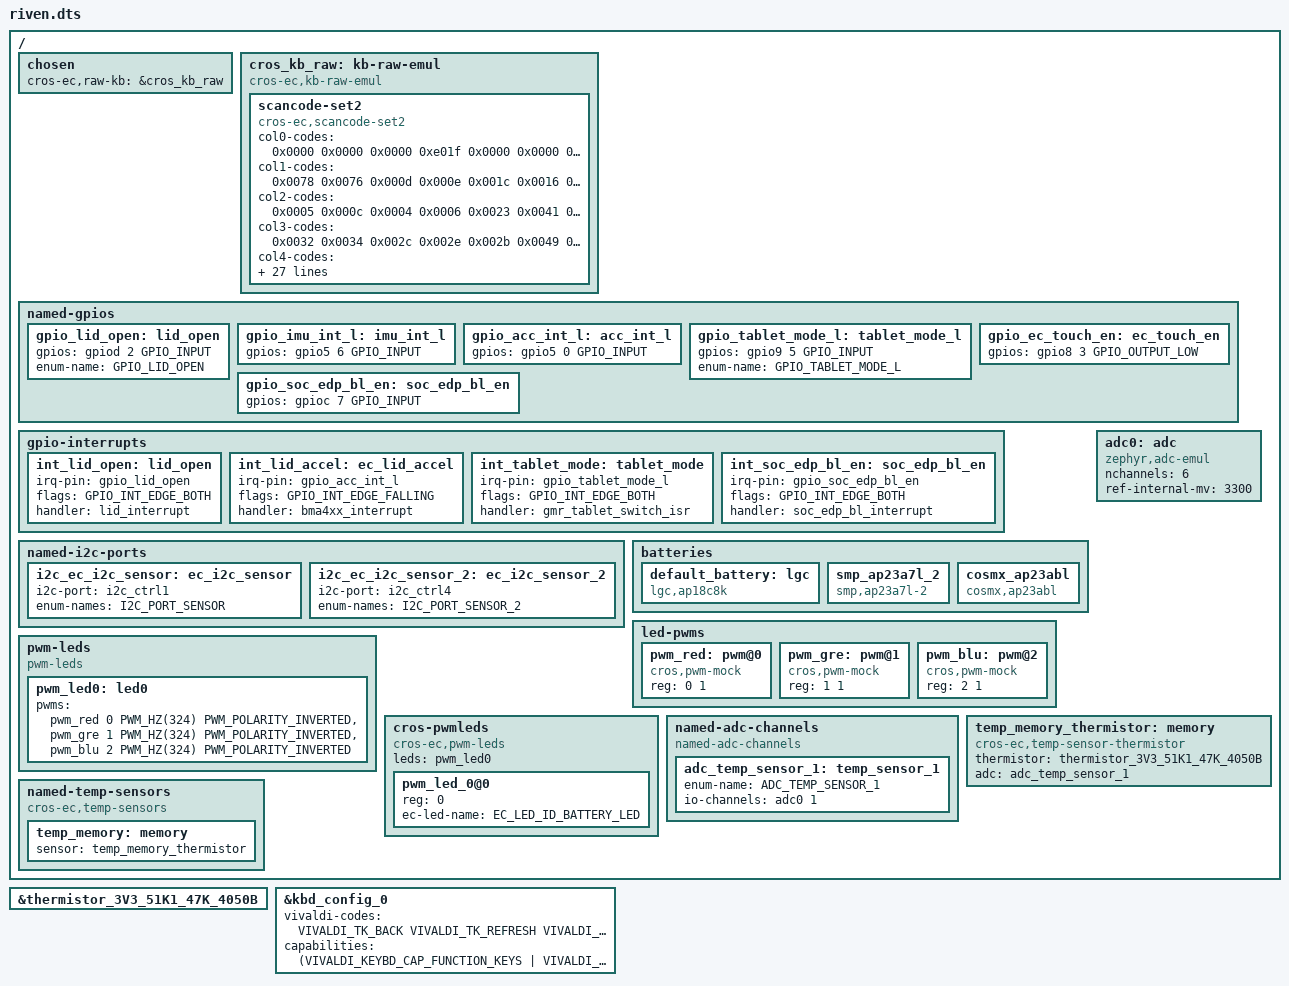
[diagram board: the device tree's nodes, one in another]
/* Copyright 2024 The ChromiumOS Authors
 * Use of this source code is governed by a BSD-style license that can be
 * found in the LICENSE file.
 */

#include <cros/thermistor/thermistor.dtsi>
#include <dt-bindings/pwm/pwm.h>
#include <cros/vivaldi_kbd_default.dtsi>

#include "generic_npcx.dts"
#include "../program/nissa/riven/cbi.dtsi"
#include "../program/nissa/riven/motionsense.dtsi"

/ {
	chosen {
		cros-ec,raw-kb = &cros_kb_raw;
	};

	cros_kb_raw: kb-raw-emul {
		compatible = "cros-ec,kb-raw-emul";
		scancode-set2 {
			compatible = "cros-ec,scancode-set2";
			col0-codes  = <0x0000 0x0000 0x0000 0xe01f 0x0000 0x0000 0x0000 0x0000>;
			col1-codes  = <0x0078 0x0076 0x000d 0x000e 0x001c 0x0016 0x001a 0x003c>;
			col2-codes  = <0x0005 0x000c 0x0004 0x0006 0x0023 0x0041 0x0026 0x0043>;
			col3-codes  = <0x0032 0x0034 0x002c 0x002e 0x002b 0x0049 0x0025 0x0044>;
			col4-codes  = <0x0009 0x0083 0x000b 0x001b 0x0003 0x004a 0x001e 0x004d>;
			col5-codes  = <0x0031 0x0007 0x005b 0x000f 0x0042 0x0021 0x003e 0x0015>;
			col6-codes  = <0x0051 0x0033 0x0035 0x004e 0x003b 0x0029 0x0045 0x001d>;
			col7-codes  = <0x0000 0x0000 0x0000 0x0000 0x0000 0x0012 0x0000 0x0059>;
			col8-codes  = <0x0055 0x0052 0x0054 0x0036 0x004c 0x0022 0x003d 0x0024>;
			col9-codes  = <0xe06c 0x0001 0xe071 0x002f 0x004b 0x002a 0x0046 0x002d>;
			col10-codes = <0xe011 0x0000 0x006a 0x0000 0x005d 0x0000 0x0000 0x0000>;
			col11-codes = <0x0017 0x0066 0x000a 0x005d 0x005a 0x003a 0xe072 0xe075>;
			col12-codes = <0x001f 0x0064 0xe07d 0x0067 0xe069 0xe07a 0xe074 0xe06b>;
			col13-codes = <0x0000 0x0000 0x0000 0x0000 0x0000 0x0000 0x0011 0x0000>;
			col14-codes = <0x0000 0x0014 0x0000 0xe014 0x0000 0x0000 0x0000 0x0000>;
			col15-codes = <0x0000 0x0000 0x0000 0x0000 0x0000 0x0000 0x0027 0x0000>;
			col16-codes = <0x0037 0x0037 0x0000 0x0000 0x0000 0x0000 0x0000 0x0000>;
			col17-codes = <0x0000 0x0000 0x006a 0x0000 0x0000 0x0000 0x005d 0x0061>;
		};
	};

	named-gpios {
		gpio_lid_open: lid_open {
			gpios = <&gpiod 2 GPIO_INPUT>;
			enum-name = "GPIO_LID_OPEN";
		};
		gpio_imu_int_l: imu_int_l {
			gpios = <&gpio5 6 GPIO_INPUT>;
		};
		gpio_acc_int_l: acc_int_l {
			gpios = <&gpio5 0 GPIO_INPUT>;
		};
		gpio_tablet_mode_l: tablet_mode_l {
			gpios = <&gpio9 5 GPIO_INPUT>;
			enum-name = "GPIO_TABLET_MODE_L";
		};
		gpio_ec_touch_en: ec_touch_en {
			gpios = <&gpio8 3 GPIO_OUTPUT_LOW>;
		};
		gpio_soc_edp_bl_en: soc_edp_bl_en {
			gpios = <&gpioc 7 GPIO_INPUT>;
		};
	};

	gpio-interrupts {
		int_lid_open: lid_open {
			irq-pin = <&gpio_lid_open>;
			flags = <GPIO_INT_EDGE_BOTH>;
			handler = "lid_interrupt";
		};
		int_lid_accel: ec_lid_accel {
			irq-pin = <&gpio_acc_int_l>;
			flags = <GPIO_INT_EDGE_FALLING>;
			handler = "bma4xx_interrupt";
		};
		int_tablet_mode: tablet_mode {
			irq-pin = <&gpio_tablet_mode_l>;
			flags = <GPIO_INT_EDGE_BOTH>;
			handler = "gmr_tablet_switch_isr";
		};
		int_soc_edp_bl_en: soc_edp_bl_en {
			irq-pin = <&gpio_soc_edp_bl_en>;
			flags = <GPIO_INT_EDGE_BOTH>;
			handler = "soc_edp_bl_interrupt";
		};
	};

	named-i2c-ports {
		i2c_ec_i2c_sensor: ec_i2c_sensor {
			i2c-port = <&i2c_ctrl1>;
			enum-names = "I2C_PORT_SENSOR";
		};
		i2c_ec_i2c_sensor_2: ec_i2c_sensor_2 {
			i2c-port = <&i2c_ctrl4>;
			enum-names = "I2C_PORT_SENSOR_2";
		};
	};

	batteries {
		default_battery: lgc {
			compatible = "lgc,ap18c8k", "battery-smart";
		};
		smp_ap23a7l_2 {
			compatible = "smp,ap23a7l-2", "battery-smart";
		};
		cosmx_ap23abl {
			compatible = "cosmx,ap23abl", "battery-smart";
		};
	};

	/* LEDs need to exist for testing, but aren't actually used. */
	led-pwms {
		#address-cells = <1>;
		#size-cells = <1>;

		pwm_red: pwm@0 {
			compatible = "cros,pwm-mock";
			reg = <0 1>;
			#pwm-cells = <3>;
		};
		pwm_gre: pwm@1 {
			compatible = "cros,pwm-mock";
			reg = <1 1>;
			#pwm-cells = <3>;
		};
		pwm_blu: pwm@2 {
			compatible = "cros,pwm-mock";
			reg = <2 1>;
			#pwm-cells = <3>;
		};
	};

	pwm-leds {
		compatible = "pwm-leds";

		pwm_led0: led0 {
			pwms = <&pwm_red 0 PWM_HZ(324) PWM_POLARITY_INVERTED>,
			       <&pwm_gre 1 PWM_HZ(324) PWM_POLARITY_INVERTED>,
			       <&pwm_blu 2 PWM_HZ(324) PWM_POLARITY_INVERTED>;
		};
	};

	cros-pwmleds {
		compatible = "cros-ec,pwm-leds";
		leds = <&pwm_led0>;

		#address-cells = <1>;
		#size-cells = <0>;

		pwm_led_0@0 {
			reg = <0>;
			ec-led-name = "EC_LED_ID_BATTERY_LED";
		};
	};

	adc0: adc {
		compatible = "zephyr,adc-emul";
		nchannels = <6>;
		ref-internal-mv = <3300>;
		#io-channel-cells = <1>;
		status = "okay";
	};

	named-adc-channels {
		compatible = "named-adc-channels";

		adc_temp_sensor_1: temp_sensor_1 {
			enum-name = "ADC_TEMP_SENSOR_1";
			io-channels = <&adc0 1>;
		};
	};

	temp_memory_thermistor: memory {
		compatible = "cros-ec,temp-sensor-thermistor";
		thermistor = <&thermistor_3V3_51K1_47K_4050B>;
		adc = <&adc_temp_sensor_1>;
	};

	named-temp-sensors {
		compatible = "cros-ec,temp-sensors";
		temp_memory: memory {
			status = "okay";
			sensor = <&temp_memory_thermistor>;
		};
	};
};

&thermistor_3V3_51K1_47K_4050B  {
	status = "okay";
};

&kbd_config_0 {
	vivaldi-codes = <
		VIVALDI_TK_BACK             /* T1 */
		VIVALDI_TK_REFRESH          /* T2 */
		VIVALDI_TK_FULLSCREEN       /* T3 */
		VIVALDI_TK_OVERVIEW         /* T4 */
		VIVALDI_TK_SNAPSHOT         /* T5 */
		VIVALDI_TK_BRIGHTNESS_DOWN  /* T6 */
		VIVALDI_TK_BRIGHTNESS_UP    /* T7 */
		VIVALDI_TK_DICTATE          /* T8 */
		VIVALDI_TK_ACCESSIBILITY    /* T9 */
		VIVALDI_TK_PLAY_PAUSE       /* T10 */
		VIVALDI_TK_MICMUTE          /* T11 */
		VIVALDI_TK_VOL_MUTE         /* T12 */
		VIVALDI_TK_VOL_DOWN         /* T13 */
		VIVALDI_TK_VOL_UP           /* T14 */
	>;
	capabilities = <(VIVALDI_KEYBD_CAP_FUNCTION_KEYS |
			VIVALDI_KEYBD_CAP_SCRNLOCK_KEY |
			VIVALDI_KEYBD_CAP_ASSISTANT_KEY)>;
};
